# SIM3C166_B register map
File version: 1
CPU: 
Registers are 32-bit, read-write, reset 0x0 unless marked. A register's access mark holds for its fields unless they carry their own. Offsets are from the block's base; [hi:lo] are bit positions; {n}, {i} and the like mark numbered series.

## PLL_0
Base 0x4003B000
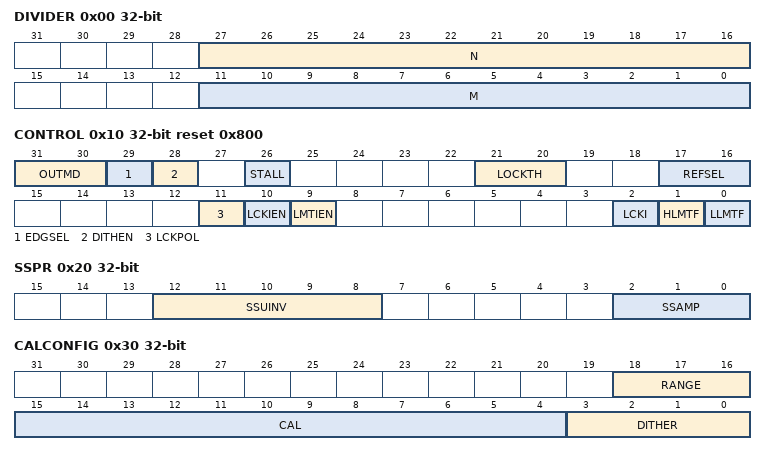
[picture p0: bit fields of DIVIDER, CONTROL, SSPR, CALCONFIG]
0x00 DIVIDER — Reference Divider Setting
  [27:16] N — N Divider Value.
  [11:0] M — M Divider Value.
0x10 CONTROL reset 0x800 — Module Control
  [31:30] OUTMD — PLL Output Mode.
    0=OFF (DCO output is off.); 1=DCO (DCO output is in Free-Running DCO mode.); 2=FLL (DCO output is in frequency-lock mode (reference source required).); 3=PLL (DCO output is in phase-lock mode (reference source required).)
  [29] EDGSEL — Edge Lock Select.
    0=FALLING_EDGE (Lock DCO output frequency to the falling edge of the reference frequency.); 1=RISING_EDGE (Lock DCO output frequency to the rising edge of the reference frequency.)
  [28] DITHEN — Dithering Enable.
    0=DISABLED (Automatic DCO output dithering disabled.); 1=ENABLED (Automatic DCO output dithering enabled.)
  [26] STALL — DCO Output Updates Stall.
    0=DISABLED (In phase-lock and frequency-lock modes, spectrum spreading, and dithering operate normally, if enabled.); 1=ENABLED (In phase-lock and frequency-lock modes, spectrum spreading, and dithering are prevented from updating the output of the DCO.)
  [21:20] LOCKTH — Lock Threshold Control.
  [17:16] REFSEL — Reference Clock Selection Control.
    0=RTC0OSC (PLL reference clock (FREF) is the RTC0 oscillator (RTC0OSC).); 1=LPOSC0DIV (PLL reference clock (FREF) is the divided Low Power Oscillator (LPOSC0).); 2=EXTOSC0 (PLL reference clock (FREF) is the external oscillator output (EXTOSC0).); 3=USBOSC0 (PLL reference clock (FREF) is the USB0 oscillator (USB0OSC).)
  [11] LCKPOL — Lock Interrupt Polarity.
    0=ACTIVE_LOW (The lock state PLL interrupt will occur when LCKI is 0.); 1=ACTIVE_HIGH (The lock state PLL interrupt will occur when LCKI is 1.)
  [10] LCKIEN — Locked Interrupt Enable.
    0=DISABLED (The PLL locking does not cause an interrupt); 1=ENABLED (An interrupt is generated if LCKI matches the state selected by LCKPOL.)
  [9] LMTIEN — Limit Interrupt Enable.
    0=DISABLED (Saturation (high and low) interrupt disabled.); 1=ENABLED (Saturation (high and low) interrupt enabled.)
  [2] LCKI ro — Phase-Lock and Frequency-Lock Locked Interrupt Flag.
    0=NOT_SET (DCO is disabled or not locked.); 1=SET (DCO is enabled and locked.)
  [1] HLMTF ro — CAL Saturation (High) Flag.
    0=NOT_SET (DCO period is not saturated high.); 1=SET (DCO period is saturated high.)
  [0] LLMTF ro — CAL Saturation (Low) Flag.
    0=NOT_SET (DCO period is not saturated low.); 1=SET (DCO period is saturated low.)
0x20 SSPR — Spectrum Spreading Control
  [12:8] SSUINV — Spectrum Spreading Update Interval.
  [2:0] SSAMP — Spectrum Spreading Amplitude.
    0=DISABLED (Disable Spectrum Spreading.); 1=SETTING1 (Spectrum Spreading set to approximately +/- 0.1% of TDCO.); 2=SETTING2 (Spectrum Spreading set to approximately +/- 0.2% of TDCO.); 3=SETTING3 (Spectrum Spreading set to approximately +/- 0.4% of TDCO.); 4=SETTING4 (Spectrum Spreading set to approximately +/- 0.8% of TDCO.); 5=SETTING5 (Spectrum Spreading set to approximately +/- 1.6% of TDCO.)
0x30 CALCONFIG — Calibration Configuration
  [18:16] RANGE — DCO Range.
    0=DCO operates from 23 to 37 MHz; 1=DCO operates from 33 to 54 MHz; 2=DCO operates from 45 to 71 MHz; 3=DCO operates from 53 to 80 MHz; 4=DCO operates from 73 to 80 MHz
  [15:4] CAL — DCO Calibration Value.
  [3:0] DITHER — DCO Dither Setting.

## EXTOSC_0
Base 0x4003C000
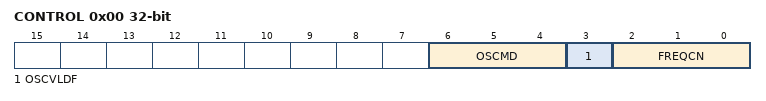
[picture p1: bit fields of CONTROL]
0x00 CONTROL — Oscillator Control
  [6:4] OSCMD — Oscillator Mode.
    0=OFF (External oscillator off.); 2=CMOS (External CMOS clock mode.); 3=CMOSDIV2 (External CMOS with divide by 2 stage.); 4=RC (RC oscillator mode with divide by 2 stage.); 5=C (C oscillator mode with divide by 2 stage.); 6=XTAL (Crystal oscillator mode.); 7=XTALDIV2 (Crystal oscillator mode with divide by 2 stage.)
  [3] OSCVLDF ro — Oscillator Valid Flag.
    0=NOT_SET (The external oscillator is unused or not yet stable.); 1=SET (The external oscillator is running and stable.)
  [2:0] FREQCN — Frequency Control.
    {v}=RANGE{v} (Set the external oscillator to range {v}.) (v=0..7)
